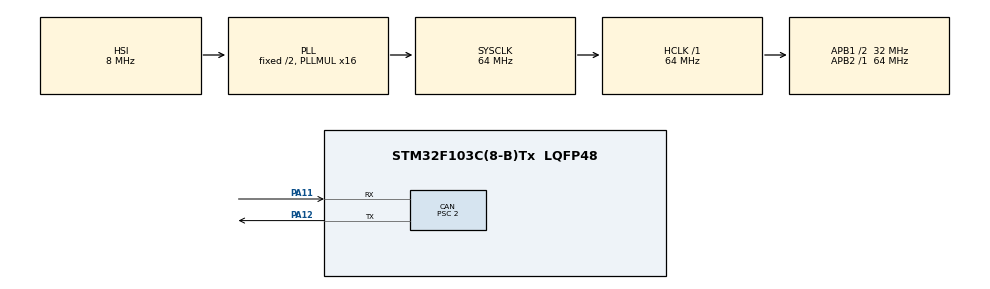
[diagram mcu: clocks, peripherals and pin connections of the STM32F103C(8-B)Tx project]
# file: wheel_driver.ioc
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CAN.BS1=CAN_BS1_14TQ
CAN.CalculateBaudRate=1000000
CAN.CalculateTimeBit=1000
CAN.CalculateTimeQuantum=62.5
CAN.Prescaler=2
Mcu.Family=STM32F1
Mcu.Name=STM32F103C(8-B)Tx
Mcu.Package=LQFP48
NVIC.PriorityGroup=NVIC_PRIORITYGROUP_4
NVIC.USB_LP_CAN1_RX0_IRQn=true\:0\:0\:false\:false\:true\:true\:true\:true
PA11.Mode=CAN_Activate
PA11.Signal=CAN_RX
PA12.Mode=CAN_Activate
PA12.Signal=CAN_TX
PA13.Mode=Serial_Wire
PA13.Signal=SYS_JTMS-SWDIO
PA14.Mode=Serial_Wire
PA14.Signal=SYS_JTCK-SWCLK
ProjectManager.HeapSize=0x200
ProjectManager.StackSize=0x400
ProjectManager.TargetToolchain=STM32CubeIDE
RCC.AHBFreq_Value=64000000
RCC.APB1CLKDivider=RCC_HCLK_DIV2
RCC.APB1Freq_Value=32000000
RCC.APB1TimFreq_Value=64000000
RCC.APB2Freq_Value=64000000
RCC.APB2TimFreq_Value=64000000
RCC.HCLKFreq_Value=64000000
RCC.PLLMUL=RCC_PLL_MUL16
RCC.SYSCLKFreq_VALUE=64000000
RCC.SYSCLKSource=RCC_SYSCLKSOURCE_PLLCLK
RCC.USBFreq_Value=64000000
board=custom

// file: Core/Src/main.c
/* USER CODE BEGIN Header */
/**
  ******************************************************************************
  * @file           : main.c
  * @brief          : Main program body
  ******************************************************************************
  * @attention
  *
  * Copyright (c) 2026 STMicroelectronics.
  * All rights reserved.
  *
  * This software is licensed under terms that can be found in the LICENSE file
  * in the root directory of this software component.
  * If no LICENSE file comes with this software, it is provided AS-IS.
  *
  ******************************************************************************
  */
/* USER CODE END Header */
#include "main.h"

CAN_HandleTypeDef hcan;

void SystemClock_Config(void);
static void MX_GPIO_Init(void);
static void MX_CAN_Init(void);

/* USER CODE BEGIN 0 */
CAN_RxHeaderTypeDef RxHeader;
uint8_t RxData[8];
volatile uint8_t datacheck = 0U;
/* USER CODE END 0 */

int main(void)
{

  /* MCU Configuration--------------------------------------------------------*/

  /* Reset of all peripherals, Initializes the Flash interface and the Systick. */
  HAL_Init();

  /* Configure the system clock */
  SystemClock_Config();

  /* Initialize all configured peripherals */
  MX_GPIO_Init();
  MX_CAN_Init();

  /* Infinite loop */
  while (1)
  {

  }
}

void SystemClock_Config(void)
{
  RCC_OscInitTypeDef RCC_OscInitStruct = {0};
  RCC_ClkInitTypeDef RCC_ClkInitStruct = {0};

  /** Initializes the RCC Oscillators according to the specified parameters
  * in the RCC_OscInitTypeDef structure.
  */
  RCC_OscInitStruct.OscillatorType = RCC_OSCILLATORTYPE_HSI;
  RCC_OscInitStruct.HSIState = RCC_HSI_ON;
  RCC_OscInitStruct.HSICalibrationValue = RCC_HSICALIBRATION_DEFAULT;
  RCC_OscInitStruct.PLL.PLLState = RCC_PLL_ON;
  RCC_OscInitStruct.PLL.PLLSource = RCC_PLLSOURCE_HSI_DIV2;
  RCC_OscInitStruct.PLL.PLLMUL = RCC_PLL_MUL16;
  if (HAL_RCC_OscConfig(&RCC_OscInitStruct) != HAL_OK)
  {
    Error_Handler();
  }

  /** Initializes the CPU, AHB and APB buses clocks
  */
  RCC_ClkInitStruct.ClockType = RCC_CLOCKTYPE_HCLK|RCC_CLOCKTYPE_SYSCLK
                              |RCC_CLOCKTYPE_PCLK1|RCC_CLOCKTYPE_PCLK2;
  RCC_ClkInitStruct.SYSCLKSource = RCC_SYSCLKSOURCE_PLLCLK;
  RCC_ClkInitStruct.AHBCLKDivider = RCC_SYSCLK_DIV1;
  RCC_ClkInitStruct.APB1CLKDivider = RCC_HCLK_DIV2;
  RCC_ClkInitStruct.APB2CLKDivider = RCC_HCLK_DIV1;

  if (HAL_RCC_ClockConfig(&RCC_ClkInitStruct, FLASH_LATENCY_2) != HAL_OK)
  {
    Error_Handler();
  }
}

static void MX_CAN_Init(void)
{

  hcan.Instance = CAN1;
  hcan.Init.Prescaler = 2;
  hcan.Init.Mode = CAN_MODE_NORMAL;
  hcan.Init.SyncJumpWidth = CAN_SJW_1TQ;
  hcan.Init.TimeSeg1 = CAN_BS1_14TQ;
  hcan.Init.TimeSeg2 = CAN_BS2_1TQ;
  hcan.Init.TimeTriggeredMode = DISABLE;
  hcan.Init.AutoBusOff = DISABLE;
  hcan.Init.AutoWakeUp = DISABLE;
  hcan.Init.AutoRetransmission = DISABLE;
  hcan.Init.ReceiveFifoLocked = DISABLE;
  hcan.Init.TransmitFifoPriority = DISABLE;
  if (HAL_CAN_Init(&hcan) != HAL_OK)
  {
    Error_Handler();
  }
  /* USER CODE BEGIN CAN_Init 2 */
  CAN_FilterTypeDef f = {0};
  f.FilterBank = 0;
  f.FilterMode = CAN_FILTERMODE_IDMASK;
  f.FilterScale = CAN_FILTERSCALE_32BIT;
  f.FilterMaskIdHigh = 0x0000;   // all-zero mask = accept everything
  f.FilterMaskIdLow  = 0x0000;
  f.FilterIdHigh     = 0x0000;
  f.FilterIdLow      = 0x0000;
  f.FilterFIFOAssignment = CAN_FILTER_FIFO0;
  f.FilterActivation = CAN_FILTER_ENABLE;
  if (HAL_CAN_ConfigFilter(&hcan, &f) != HAL_OK)
  {
	  Error_Handler();
  }

  if (HAL_CAN_ActivateNotification(&hcan, CAN_IT_RX_FIFO0_MSG_PENDING) != HAL_OK)
  {
	  Error_Handler();
  }

  if (HAL_CAN_Start(&hcan) != HAL_OK)
  {
    Error_Handler();
  }
  /* USER CODE END CAN_Init 2 */

}

static void MX_GPIO_Init(void)
{

  /* GPIO Ports Clock Enable */
  __HAL_RCC_GPIOA_CLK_ENABLE();

}

/* USER CODE BEGIN 4 */
void HAL_CAN_RxFifo0MsgPendingCallback(CAN_HandleTypeDef *hcan)
{
  if (HAL_CAN_GetRxMessage(hcan, CAN_RX_FIFO0, &RxHeader, RxData) != HAL_OK)
  {
    Error_Handler();
  }
  if ((RxHeader.StdId == 0x446))
  {
	  datacheck = 1;
  }
}
/* USER CODE END 4 */

void Error_Handler(void)
{
  __disable_irq();
  while (1)
  {
  }
}
